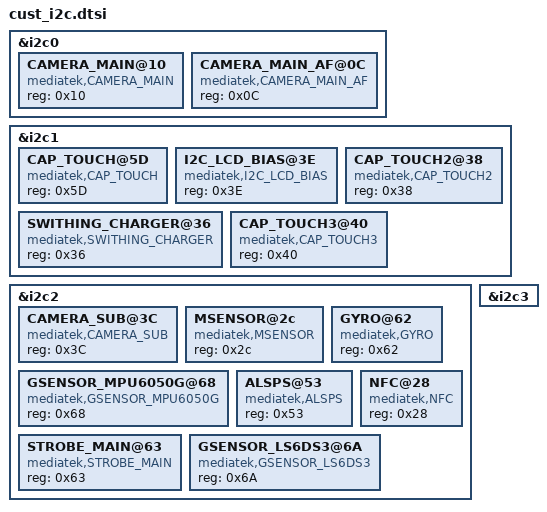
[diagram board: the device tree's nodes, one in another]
/*
 * Generated by MTK SP DrvGen Version 03.13.6 for MT6735. Copyright MediaTek Inc. (C) 2013.
 * Fri Oct 21 17:30:06 2016
 * Do Not Modify the File.
 */

/*************************
 * I2C DTSI File
*************************/

&i2c0 {
	CAMERA_MAIN@10 {
		compatible = "mediatek,CAMERA_MAIN";
		reg = <0x10>;
	};

	CAMERA_MAIN_AF@0C {
		compatible = "mediatek,CAMERA_MAIN_AF";
		reg = <0x0C>;
	};

};

&i2c1 {
	CAP_TOUCH@5D {
		compatible = "mediatek,CAP_TOUCH";
		reg = <0x5D>;
	};

	I2C_LCD_BIAS@3E {
		compatible = "mediatek,I2C_LCD_BIAS";
		reg = <0x3E>;
	};

	SWITHING_CHARGER@36 {
		compatible = "mediatek,SWITHING_CHARGER";
		reg = <0x36>;
	};

	CAP_TOUCH2@38 {
		compatible = "mediatek,CAP_TOUCH2";
		reg = <0x38>;
	};

	CAP_TOUCH3@40 {
		compatible = "mediatek,CAP_TOUCH3";
		reg = <0x40>;
	};

};

&i2c2 {
	CAMERA_SUB@3C {
		compatible = "mediatek,CAMERA_SUB";
		reg = <0x3C>;
	};

	MSENSOR@2c {
		compatible = "mediatek,MSENSOR";
		reg = <0x2c>;
	};

	GYRO@62 {
		compatible = "mediatek,GYRO";
		reg = <0x62>;
	};

	GSENSOR_MPU6050G@68 {
		compatible = "mediatek,GSENSOR_MPU6050G";
		reg = <0x68>;
	};

	ALSPS@53 {
		compatible = "mediatek,ALSPS";
		reg = <0x53>;
	};

	NFC@28 {
		compatible = "mediatek,NFC";
		reg = <0x28>;
	};

	STROBE_MAIN@63 {
		compatible = "mediatek,STROBE_MAIN";
		reg = <0x63>;
	};

	GSENSOR_LS6DS3@6A {
		compatible = "mediatek,GSENSOR_LS6DS3";
		reg = <0x6A>;
	};

};

&i2c3 {
};

